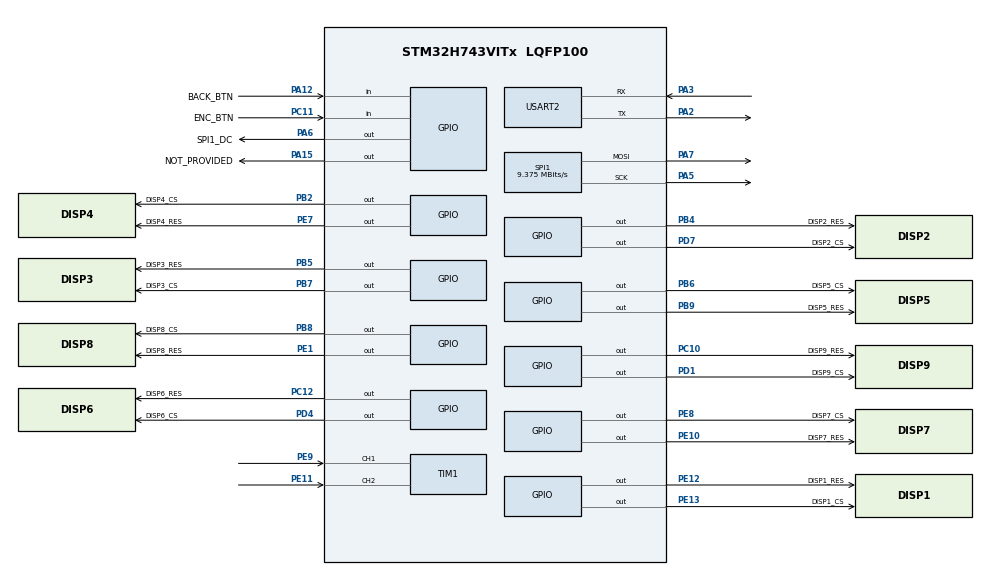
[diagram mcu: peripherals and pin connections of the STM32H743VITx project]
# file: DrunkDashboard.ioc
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FREERTOS.Tasks01=testTask,24,20000,StartTestTask,Default,NULL,Dynamic,NULL,NULL
FREERTOS.configTOTAL_HEAP_SIZE=110000
Mcu.Family=STM32H7
Mcu.Name=STM32H743VITx
Mcu.Package=LQFP100
NVIC.PriorityGroup=NVIC_PRIORITYGROUP_4
PA12.GPIO_Label=BACK_BTN
PA12.Signal=GPIO_Input
PA13\ (JTMS/SWDIO).Mode=Serial_Wire
PA13\ (JTMS/SWDIO).Signal=DEBUG_JTMS-SWDIO
PA14\ (JTCK/SWCLK).Mode=Serial_Wire
PA14\ (JTCK/SWCLK).Signal=DEBUG_JTCK-SWCLK
PA15\ (JTDI).GPIO_Label=NOT_PROVIDED
PA15\ (JTDI).Signal=GPIO_Output
PA2.Mode=Asynchronous
PA2.Signal=USART2_TX
PA3.Mode=Asynchronous
PA3.Signal=USART2_RX
PA5.Mode=TX_Only_Simplex_Unidirect_Master
PA5.Signal=SPI1_SCK
PA6.GPIO_Label=SPI1_DC
PA6.GPIO_Speed=GPIO_SPEED_FREQ_LOW
PA6.Signal=GPIO_Output
PA7.Mode=TX_Only_Simplex_Unidirect_Master
PA7.Signal=SPI1_MOSI
PB2.GPIO_Label=DISP4_CS
PB2.GPIO_PuPd=GPIO_PULLUP
PB2.Signal=GPIO_Output
PB4\ (NJTRST).GPIO_Label=DISP2_RES
PB4\ (NJTRST).GPIO_PuPd=GPIO_PULLUP
PB4\ (NJTRST).Signal=GPIO_Output
PB5.GPIO_Label=DISP3_RES
PB5.GPIO_PuPd=GPIO_PULLUP
PB5.Signal=GPIO_Output
PB6.GPIO_Label=DISP5_CS
PB6.GPIO_PuPd=GPIO_PULLUP
PB6.Signal=GPIO_Output
PB7.GPIO_Label=DISP3_CS
PB7.GPIO_PuPd=GPIO_PULLUP
PB7.Signal=GPIO_Output
PB8.GPIO_Label=DISP8_CS
PB8.GPIO_PuPd=GPIO_PULLUP
PB8.Signal=GPIO_Output
PB9.GPIO_Label=DISP5_RES
PB9.GPIO_PuPd=GPIO_PULLUP
PB9.Signal=GPIO_Output
PC10.GPIO_Label=DISP9_RES
PC10.GPIO_PuPd=GPIO_PULLUP
PC10.Signal=GPIO_Output
PC11.GPIO_Label=ENC_BTN
PC11.GPIO_PuPd=GPIO_PULLUP
PC11.Signal=GPIO_Input
PC12.GPIO_Label=DISP6_RES
PC12.GPIO_PuPd=GPIO_PULLUP
PC12.Signal=GPIO_Output
PD1.GPIO_Label=DISP9_CS
PD1.GPIO_PuPd=GPIO_PULLUP
PD1.Signal=GPIO_Output
PD4.GPIO_Label=DISP6_CS
PD4.GPIO_PuPd=GPIO_PULLUP
PD4.Signal=GPIO_Output
PD7.GPIO_Label=DISP2_CS
PD7.GPIO_PuPd=GPIO_PULLUP
PD7.Signal=GPIO_Output
PE1.GPIO_Label=DISP8_RES
PE1.GPIO_PuPd=GPIO_PULLUP
PE1.Signal=GPIO_Output
PE10.GPIO_Label=DISP7_RES
PE10.GPIO_PuPd=GPIO_PULLUP
PE10.Signal=GPIO_Output
PE11.Signal=S_TIM1_CH2
PE12.GPIO_Label=DISP1_RES
PE12.GPIO_PuPd=GPIO_PULLUP
PE12.Signal=GPIO_Output
PE13.GPIO_Label=DISP1_CS
PE13.GPIO_PuPd=GPIO_PULLUP
PE13.Signal=GPIO_Output
PE7.GPIO_Label=DISP4_RES
PE7.GPIO_PuPd=GPIO_PULLUP
PE7.Signal=GPIO_Output
PE8.GPIO_Label=DISP7_CS
PE8.GPIO_PuPd=GPIO_PULLUP
PE8.Signal=GPIO_Output
PE9.Signal=S_TIM1_CH1
PH0-OSC_IN\ (PH0).Mode=HSE-External-Oscillator
PH0-OSC_IN\ (PH0).Signal=RCC_OSC_IN
PH1-OSC_OUT\ (PH1).Mode=HSE-External-Oscillator
PH1-OSC_OUT\ (PH1).Signal=RCC_OSC_OUT
ProjectManager.HeapSize=0x200
ProjectManager.StackSize=0x400
ProjectManager.TargetToolchain=Makefile
RCC.ADCFreq_Value=150000000
RCC.APB1Freq_Value=100000000
RCC.APB2Freq_Value=100000000
RCC.APB3Freq_Value=100000000
RCC.APB4Freq_Value=100000000
RCC.CKPERSourceSelection=RCC_CLKPSOURCE_HSE
RCC.CortexFreq_Value=400000000
RCC.D1PPRE=RCC_APB3_DIV2
RCC.D2PPRE1=RCC_APB1_DIV2
RCC.D2PPRE2=RCC_APB2_DIV2
RCC.D3PPRE=RCC_APB4_DIV2
RCC.DIVM1=2
RCC.DIVM2=2
RCC.DIVN1=64
RCC.DIVN2=12
RCC.DIVP2=1
RCC.DIVQ1=4
RCC.EnbaleCSS=true
RCC.HCLKFreq_Value=200000000
RCC.HPRE=RCC_HCLK_DIV2
RCC.PLL2FRACN=0
RCC.PLL3FRACN=0
RCC.PLLFRACN=0
RCC.PLLSourceVirtual=RCC_PLLSOURCE_HSE
RCC.PWR_Regulator_Voltage_Scale=PWR_REGULATOR_VOLTAGE_SCALE1
RCC.SPI123CLockSelection=RCC_SPI123CLKSOURCE_PLL2
RCC.SPI6CLockSelection=RCC_SPI6CLKSOURCE_HSI
RCC.SYSCLKFreq_VALUE=400000000
RCC.SYSCLKSource=RCC_SYSCLKSOURCE_PLLCLK
RCC.USBFreq_Value=200000000
SH.S_TIM1_CH1.0=TIM1_CH1,Encoder_Interface
SH.S_TIM1_CH2.0=TIM1_CH2,Encoder_Interface
SPI1.BaudRatePrescaler=SPI_BAUDRATEPRESCALER_16
SPI1.CLKPolarity=SPI_POLARITY_LOW
SPI1.CalculateBaudRate=9.375 MBits/s
SPI1.DataSize=SPI_DATASIZE_8BIT
SPI1.Direction=SPI_DIRECTION_2LINES_TXONLY
SPI1.FifoThreshold=SPI_FIFO_THRESHOLD_01DATA
SPI1.FirstBit=SPI_FIRSTBIT_MSB
SPI1.MasterKeepIOState=SPI_MASTER_KEEP_IO_STATE_ENABLE
SPI1.Mode=SPI_MODE_MASTER
SPI1.NSSPMode=SPI_NSS_PULSE_ENABLE
SPI1.NSSPolarity=SPI_NSS_POLARITY_LOW
SPI1.VirtualType=VM_MASTER
USART2.VirtualMode-Asynchronous=VM_ASYNC
VP_FREERTOS_VS_CMSIS_V2.Mode=CMSIS_V2
board=custom

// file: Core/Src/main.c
/* USER CODE BEGIN Header */
/**
  ******************************************************************************
  * @file           : main.c
  * @brief          : Main program body
  ******************************************************************************
  * @attention
  *
  * Copyright (c) 2023 STMicroelectronics.
  * All rights reserved.
  *
  * This software is licensed under terms that can be found in the LICENSE file
  * in the root directory of this software component.
  * If no LICENSE file comes with this software, it is provided AS-IS.
  *
  ******************************************************************************
  */
/* USER CODE END Header */
#include "main.h"
#include "cmsis_os.h"

/* USER CODE BEGIN Includes */
#include <system.h>

/* USER CODE END Includes */

/* Definitions for testTask */
osThreadId_t testTaskHandle;
const osThreadAttr_t testTask_attributes = {
  .name = "testTask",
  .stack_size = 2048,
  .priority = (osPriority_t) osPriorityNormal,
};

void SystemClock_Config(void);
void PeriphCommonClock_Config(void);
static void MX_GPIO_Init(void);
static void MX_SPI1_Init(void);
static void MX_TIM1_Init(void);
static void MX_USART2_UART_Init(void);
void StartTestTask(void *argument);

int main(void)
{

  /* MCU Configuration--------------------------------------------------------*/

  /* Reset of all peripherals, Initializes the Flash interface and the Systick. */
  LL_APB4_GRP1_EnableClock(LL_APB4_GRP1_PERIPH_SYSCFG);

  /* System interrupt init*/
  NVIC_SetPriorityGrouping(NVIC_PRIORITYGROUP_4);

  /* PendSV_IRQn interrupt configuration */
  NVIC_SetPriority(PendSV_IRQn, NVIC_EncodePriority(NVIC_GetPriorityGrouping(),15, 0));
  /* SysTick_IRQn interrupt configuration */
  NVIC_SetPriority(SysTick_IRQn, NVIC_EncodePriority(NVIC_GetPriorityGrouping(),15, 0));

  /* Configure the system clock */
  SystemClock_Config();

/* Configure the peripherals common clocks */
  PeriphCommonClock_Config();

  /* Initialize all configured peripherals */
  MX_GPIO_Init();
  MX_SPI1_Init();
  MX_TIM1_Init();
  MX_USART2_UART_Init();
  /* USER CODE BEGIN 2 */
  system_init();
  /* USER CODE END 2 */

  /* Init scheduler */
  osKernelInitialize();

  /* Create the thread(s) */
  /* creation of testTask */
  testTaskHandle = osThreadNew(StartTestTask, NULL, &testTask_attributes);

  /* Start scheduler */
  osKernelStart();

  /* We should never get here as control is now taken by the scheduler */
  /* Infinite loop */
  while (1)
  {

  }
}

void SystemClock_Config(void)
{
  LL_FLASH_SetLatency(LL_FLASH_LATENCY_2);
  while(LL_FLASH_GetLatency()!= LL_FLASH_LATENCY_2)
  {
  }
  LL_PWR_ConfigSupply(LL_PWR_LDO_SUPPLY);
  LL_PWR_SetRegulVoltageScaling(LL_PWR_REGU_VOLTAGE_SCALE1);
  LL_RCC_HSE_Enable();

   /* Wait till HSE is ready */
  while(LL_RCC_HSE_IsReady() != 1)
  {

  }
  LL_RCC_HSE_EnableCSS();
  LL_RCC_PLL_SetSource(LL_RCC_PLLSOURCE_HSE);
  LL_RCC_PLL1P_Enable();
  LL_RCC_PLL1R_Enable();
  LL_RCC_PLL1_SetVCOInputRange(LL_RCC_PLLINPUTRANGE_8_16);
  LL_RCC_PLL1_SetVCOOutputRange(LL_RCC_PLLVCORANGE_WIDE);
  LL_RCC_PLL1_SetM(2);
  LL_RCC_PLL1_SetN(64);
  LL_RCC_PLL1_SetP(2);
  LL_RCC_PLL1_SetQ(4);
  LL_RCC_PLL1_SetR(2);
  LL_RCC_PLL1_Enable();

   /* Wait till PLL is ready */
  while(LL_RCC_PLL1_IsReady() != 1)
  {
  }

   /* Intermediate AHB prescaler 2 when target frequency clock is higher than 80 MHz */
   LL_RCC_SetAHBPrescaler(LL_RCC_AHB_DIV_2);

  LL_RCC_SetSysClkSource(LL_RCC_SYS_CLKSOURCE_PLL1);

   /* Wait till System clock is ready */
  while(LL_RCC_GetSysClkSource() != LL_RCC_SYS_CLKSOURCE_STATUS_PLL1)
  {

  }
  LL_RCC_SetSysPrescaler(LL_RCC_SYSCLK_DIV_1);
  LL_RCC_SetAHBPrescaler(LL_RCC_AHB_DIV_2);
  LL_RCC_SetAPB1Prescaler(LL_RCC_APB1_DIV_2);
  LL_RCC_SetAPB2Prescaler(LL_RCC_APB2_DIV_2);
  LL_RCC_SetAPB3Prescaler(LL_RCC_APB3_DIV_2);
  LL_RCC_SetAPB4Prescaler(LL_RCC_APB4_DIV_2);

  LL_Init1msTick(400000000);

  LL_SetSystemCoreClock(400000000);
  LL_RCC_HSE_EnableCSS();
}

void PeriphCommonClock_Config(void)
{
  LL_RCC_PLL2P_Enable();
  LL_RCC_PLL2_SetVCOInputRange(LL_RCC_PLLINPUTRANGE_8_16);
  LL_RCC_PLL2_SetVCOOutputRange(LL_RCC_PLLVCORANGE_MEDIUM);
  LL_RCC_PLL2_SetM(2);
  LL_RCC_PLL2_SetN(12);
  LL_RCC_PLL2_SetP(1);
  LL_RCC_PLL2_SetQ(2);
  LL_RCC_PLL2_SetR(2);
  LL_RCC_PLL2_Enable();

   /* Wait till PLL is ready */
  while(LL_RCC_PLL2_IsReady() != 1)
  {
  }

}

static void MX_SPI1_Init(void)
{

  LL_SPI_InitTypeDef SPI_InitStruct = {0};

  LL_GPIO_InitTypeDef GPIO_InitStruct = {0};

  LL_RCC_SetSPIClockSource(LL_RCC_SPI123_CLKSOURCE_PLL2P);

  /* Peripheral clock enable */
  LL_APB2_GRP1_EnableClock(LL_APB2_GRP1_PERIPH_SPI1);

  LL_AHB4_GRP1_EnableClock(LL_AHB4_GRP1_PERIPH_GPIOA);
  /**SPI1 GPIO Configuration
  PA5   ------> SPI1_SCK
  PA7   ------> SPI1_MOSI
  */
  GPIO_InitStruct.Pin = LL_GPIO_PIN_5|LL_GPIO_PIN_7;
  GPIO_InitStruct.Mode = LL_GPIO_MODE_ALTERNATE;
  GPIO_InitStruct.Speed = LL_GPIO_SPEED_FREQ_LOW;
  GPIO_InitStruct.OutputType = LL_GPIO_OUTPUT_PUSHPULL;
  GPIO_InitStruct.Pull = LL_GPIO_PULL_NO;
  GPIO_InitStruct.Alternate = LL_GPIO_AF_5;
  LL_GPIO_Init(GPIOA, &GPIO_InitStruct);

  /* SPI1 parameter configuration*/
  SPI_InitStruct.TransferDirection = LL_SPI_SIMPLEX_TX;
  SPI_InitStruct.Mode = LL_SPI_MODE_MASTER;
  SPI_InitStruct.DataWidth = LL_SPI_DATAWIDTH_8BIT;
  SPI_InitStruct.ClockPolarity = LL_SPI_POLARITY_LOW;
  SPI_InitStruct.ClockPhase = LL_SPI_PHASE_1EDGE;
  SPI_InitStruct.NSS = LL_SPI_NSS_SOFT;
  SPI_InitStruct.BaudRate = LL_SPI_BAUDRATEPRESCALER_DIV16;
  SPI_InitStruct.BitOrder = LL_SPI_MSB_FIRST;
  SPI_InitStruct.CRCCalculation = LL_SPI_CRCCALCULATION_DISABLE;
  SPI_InitStruct.CRCPoly = 0x0;
  LL_SPI_Init(SPI1, &SPI_InitStruct);
  LL_SPI_SetStandard(SPI1, LL_SPI_PROTOCOL_MOTOROLA);
  LL_SPI_EnableNSSPulseMgt(SPI1);

}

static void MX_TIM1_Init(void)
{

  LL_TIM_InitTypeDef TIM_InitStruct = {0};

  LL_GPIO_InitTypeDef GPIO_InitStruct = {0};

  /* Peripheral clock enable */
  LL_APB2_GRP1_EnableClock(LL_APB2_GRP1_PERIPH_TIM1);

  LL_AHB4_GRP1_EnableClock(LL_AHB4_GRP1_PERIPH_GPIOE);
  /**TIM1 GPIO Configuration
  PE9   ------> TIM1_CH1
  PE11   ------> TIM1_CH2
  */
  GPIO_InitStruct.Pin = LL_GPIO_PIN_9|LL_GPIO_PIN_11;
  GPIO_InitStruct.Mode = LL_GPIO_MODE_ALTERNATE;
  GPIO_InitStruct.Speed = LL_GPIO_SPEED_FREQ_LOW;
  GPIO_InitStruct.OutputType = LL_GPIO_OUTPUT_PUSHPULL;
  GPIO_InitStruct.Pull = LL_GPIO_PULL_NO;
  GPIO_InitStruct.Alternate = LL_GPIO_AF_1;
  LL_GPIO_Init(GPIOE, &GPIO_InitStruct);

  TIM_InitStruct.Prescaler = 0;
  TIM_InitStruct.CounterMode = LL_TIM_COUNTERMODE_UP;
  TIM_InitStruct.Autoreload = 65535;
  TIM_InitStruct.ClockDivision = LL_TIM_CLOCKDIVISION_DIV1;
  TIM_InitStruct.RepetitionCounter = 0;
  LL_TIM_Init(TIM1, &TIM_InitStruct);
  LL_TIM_DisableARRPreload(TIM1);
  LL_TIM_SetEncoderMode(TIM1, LL_TIM_ENCODERMODE_X2_TI1);
  LL_TIM_IC_SetActiveInput(TIM1, LL_TIM_CHANNEL_CH1, LL_TIM_ACTIVEINPUT_DIRECTTI);
  LL_TIM_IC_SetPrescaler(TIM1, LL_TIM_CHANNEL_CH1, LL_TIM_ICPSC_DIV1);
  LL_TIM_IC_SetFilter(TIM1, LL_TIM_CHANNEL_CH1, LL_TIM_IC_FILTER_FDIV1);
  LL_TIM_IC_SetPolarity(TIM1, LL_TIM_CHANNEL_CH1, LL_TIM_IC_POLARITY_RISING);
  LL_TIM_IC_SetActiveInput(TIM1, LL_TIM_CHANNEL_CH2, LL_TIM_ACTIVEINPUT_DIRECTTI);
  LL_TIM_IC_SetPrescaler(TIM1, LL_TIM_CHANNEL_CH2, LL_TIM_ICPSC_DIV1);
  LL_TIM_IC_SetFilter(TIM1, LL_TIM_CHANNEL_CH2, LL_TIM_IC_FILTER_FDIV1);
  LL_TIM_IC_SetPolarity(TIM1, LL_TIM_CHANNEL_CH2, LL_TIM_IC_POLARITY_RISING);
  LL_TIM_SetTriggerOutput(TIM1, LL_TIM_TRGO_RESET);
  LL_TIM_SetTriggerOutput2(TIM1, LL_TIM_TRGO2_RESET);
  LL_TIM_DisableMasterSlaveMode(TIM1);

}

static void MX_USART2_UART_Init(void)
{

  LL_USART_InitTypeDef USART_InitStruct = {0};

  LL_GPIO_InitTypeDef GPIO_InitStruct = {0};

  LL_RCC_SetUSARTClockSource(LL_RCC_USART234578_CLKSOURCE_PCLK1);

  /* Peripheral clock enable */
  LL_APB1_GRP1_EnableClock(LL_APB1_GRP1_PERIPH_USART2);

  LL_AHB4_GRP1_EnableClock(LL_AHB4_GRP1_PERIPH_GPIOA);
  /**USART2 GPIO Configuration
  PA2   ------> USART2_TX
  PA3   ------> USART2_RX
  */
  GPIO_InitStruct.Pin = LL_GPIO_PIN_2|LL_GPIO_PIN_3;
  GPIO_InitStruct.Mode = LL_GPIO_MODE_ALTERNATE;
  GPIO_InitStruct.Speed = LL_GPIO_SPEED_FREQ_LOW;
  GPIO_InitStruct.OutputType = LL_GPIO_OUTPUT_PUSHPULL;
  GPIO_InitStruct.Pull = LL_GPIO_PULL_NO;
  GPIO_InitStruct.Alternate = LL_GPIO_AF_7;
  LL_GPIO_Init(GPIOA, &GPIO_InitStruct);

  USART_InitStruct.PrescalerValue = LL_USART_PRESCALER_DIV1;
  USART_InitStruct.BaudRate = 115200;
  USART_InitStruct.DataWidth = LL_USART_DATAWIDTH_8B;
  USART_InitStruct.StopBits = LL_USART_STOPBITS_1;
  USART_InitStruct.Parity = LL_USART_PARITY_NONE;
  USART_InitStruct.TransferDirection = LL_USART_DIRECTION_TX_RX;
  USART_InitStruct.HardwareFlowControl = LL_USART_HWCONTROL_NONE;
  USART_InitStruct.OverSampling = LL_USART_OVERSAMPLING_16;
  LL_USART_Init(USART2, &USART_InitStruct);
  LL_USART_SetTXFIFOThreshold(USART2, LL_USART_FIFOTHRESHOLD_1_8);
  LL_USART_SetRXFIFOThreshold(USART2, LL_USART_FIFOTHRESHOLD_1_8);
  LL_USART_DisableFIFO(USART2);
  LL_USART_ConfigAsyncMode(USART2);

  LL_USART_Enable(USART2);

  /* Polling USART2 initialisation */
  while((!(LL_USART_IsActiveFlag_TEACK(USART2))) || (!(LL_USART_IsActiveFlag_REACK(USART2))))
  {
  }

}

static void MX_GPIO_Init(void)
{
  LL_GPIO_InitTypeDef GPIO_InitStruct = {0};

  /* GPIO Ports Clock Enable */
  LL_AHB4_GRP1_EnableClock(LL_AHB4_GRP1_PERIPH_GPIOH);
  LL_AHB4_GRP1_EnableClock(LL_AHB4_GRP1_PERIPH_GPIOA);
  LL_AHB4_GRP1_EnableClock(LL_AHB4_GRP1_PERIPH_GPIOB);
  LL_AHB4_GRP1_EnableClock(LL_AHB4_GRP1_PERIPH_GPIOE);
  LL_AHB4_GRP1_EnableClock(LL_AHB4_GRP1_PERIPH_GPIOC);
  LL_AHB4_GRP1_EnableClock(LL_AHB4_GRP1_PERIPH_GPIOD);

  /**/
  LL_GPIO_ResetOutputPin(GPIOA, SPI1_DC_Pin|NOT_PROVIDED_Pin);

  /**/
  LL_GPIO_ResetOutputPin(GPIOB, DISP4_CS_Pin|DISP2_RES_Pin|DISP3_RES_Pin|DISP5_CS_Pin
                          |DISP3_CS_Pin|DISP8_CS_Pin|DISP5_RES_Pin);

  /**/
  LL_GPIO_ResetOutputPin(GPIOE, DISP4_RES_Pin|DISP7_CS_Pin|DISP7_RES_Pin|DISP1_RES_Pin
                          |DISP1_CS_Pin|DISP8_RES_Pin);

  /**/
  LL_GPIO_ResetOutputPin(GPIOC, DISP9_RES_Pin|DISP6_RES_Pin);

  /**/
  LL_GPIO_ResetOutputPin(GPIOD, DISP9_CS_Pin|DISP6_CS_Pin|DISP2_CS_Pin);

  /**/
  GPIO_InitStruct.Pin = SPI1_DC_Pin|NOT_PROVIDED_Pin;
  GPIO_InitStruct.Mode = LL_GPIO_MODE_OUTPUT;
  GPIO_InitStruct.Speed = LL_GPIO_SPEED_FREQ_LOW;
  GPIO_InitStruct.OutputType = LL_GPIO_OUTPUT_PUSHPULL;
  GPIO_InitStruct.Pull = LL_GPIO_PULL_NO;
  LL_GPIO_Init(GPIOA, &GPIO_InitStruct);

  /**/
  GPIO_InitStruct.Pin = DISP4_CS_Pin|DISP2_RES_Pin|DISP3_RES_Pin|DISP5_CS_Pin
                          |DISP3_CS_Pin|DISP8_CS_Pin|DISP5_RES_Pin;
  GPIO_InitStruct.Mode = LL_GPIO_MODE_OUTPUT;
  GPIO_InitStruct.Speed = LL_GPIO_SPEED_FREQ_LOW;
  GPIO_InitStruct.OutputType = LL_GPIO_OUTPUT_PUSHPULL;
  GPIO_InitStruct.Pull = LL_GPIO_PULL_UP;
  LL_GPIO_Init(GPIOB, &GPIO_InitStruct);

  /**/
  GPIO_InitStruct.Pin = DISP4_RES_Pin|DISP7_CS_Pin|DISP7_RES_Pin|DISP1_RES_Pin
                          |DISP1_CS_Pin|DISP8_RES_Pin;
  GPIO_InitStruct.Mode = LL_GPIO_MODE_OUTPUT;
  GPIO_InitStruct.Speed = LL_GPIO_SPEED_FREQ_LOW;
  GPIO_InitStruct.OutputType = LL_GPIO_OUTPUT_PUSHPULL;
  GPIO_InitStruct.Pull = LL_GPIO_PULL_UP;
  LL_GPIO_Init(GPIOE, &GPIO_InitStruct);

  /**/
  GPIO_InitStruct.Pin = BACK_BTN_Pin;
  GPIO_InitStruct.Mode = LL_GPIO_MODE_INPUT;
  GPIO_InitStruct.Pull = LL_GPIO_PULL_NO;
  LL_GPIO_Init(BACK_BTN_GPIO_Port, &GPIO_InitStruct);

  /**/
  GPIO_InitStruct.Pin = DISP9_RES_Pin|DISP6_RES_Pin;
  GPIO_InitStruct.Mode = LL_GPIO_MODE_OUTPUT;
  GPIO_InitStruct.Speed = LL_GPIO_SPEED_FREQ_LOW;
  GPIO_InitStruct.OutputType = LL_GPIO_OUTPUT_PUSHPULL;
  GPIO_InitStruct.Pull = LL_GPIO_PULL_UP;
  LL_GPIO_Init(GPIOC, &GPIO_InitStruct);

  /**/
  GPIO_InitStruct.Pin = ENC_BTN_Pin;
  GPIO_InitStruct.Mode = LL_GPIO_MODE_INPUT;
  GPIO_InitStruct.Pull = LL_GPIO_PULL_UP;
  LL_GPIO_Init(ENC_BTN_GPIO_Port, &GPIO_InitStruct);

  /**/
  GPIO_InitStruct.Pin = DISP9_CS_Pin|DISP6_CS_Pin|DISP2_CS_Pin;
  GPIO_InitStruct.Mode = LL_GPIO_MODE_OUTPUT;
  GPIO_InitStruct.Speed = LL_GPIO_SPEED_FREQ_LOW;
  GPIO_InitStruct.OutputType = LL_GPIO_OUTPUT_PUSHPULL;
  GPIO_InitStruct.Pull = LL_GPIO_PULL_UP;
  LL_GPIO_Init(GPIOD, &GPIO_InitStruct);

}

void StartTestTask(void *argument)
{
  /* USER CODE BEGIN 5 */
  UNUSED(argument);
  /* Infinite loop */
  for(;;)
  {
    osDelay(1);
  }
  /* USER CODE END 5 */
}

void Error_Handler(void)
{
  __disable_irq();
  while (1)
  {
  }
}
